AUTOSAR XML (schema 4-3-0)
package /ComponentTypes
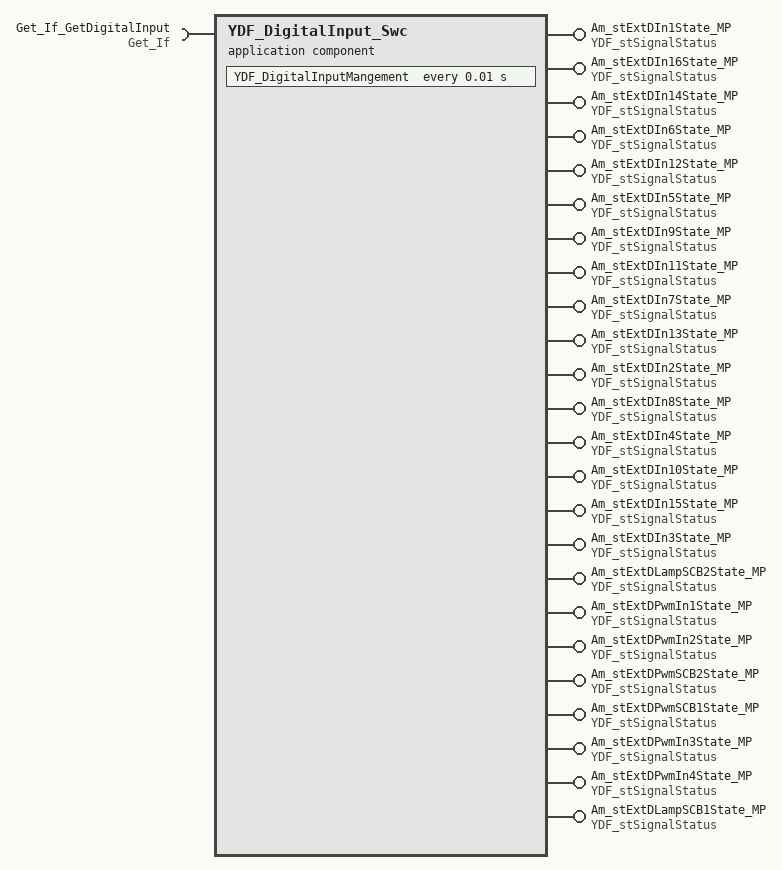
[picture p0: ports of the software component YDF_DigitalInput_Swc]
  application sw component type YDF_DigitalInput_Swc
    provide port Am_stExtDIn1State_MP: nonqueued-sender-com-spec{data-element=SignalStatus, init-value=0}, provided-interface=YDF_stSignalStatus
    provide port Am_stExtDIn16State_MP: nonqueued-sender-com-spec{data-element=SignalStatus, init-value=0}, provided-interface=YDF_stSignalStatus
    require port Get_If_GetDigitalInput: required-interface=Get_If
      required-com-specs:
        Get_Ad_Result
        Get_io_inResult
        Get_BTS_OutResult
        Get_CAN_ActiveInf
        Icu_17_GtmCcu6_PWMIN_CH{1..4}
        Icu_17_GtmCcu6_PWMIN_PWMSCB1
        Icu_17_GtmCcu6_PWMIN_PWMSCB2
        Icu_17_GtmCcu6_PWMIN_LAMPSCB1
        Icu_17_GtmCcu6_PWMIN_LAMPSCB2
        Get_Bottom_Ver
        Get_SentData
        Get_Level_OutResult
        Get_PwmOrLevel_OutResult
        Get_Motor_OutResult
    22 x provide port, all with nonqueued-sender-com-spec{data-element=SignalStatus, init-value=0}, provided-interface=YDF_stSignalStatus:
      Am_stExtDIn14State_MP
      Am_stExtDIn6State_MP
      Am_stExtDIn12State_MP
      Am_stExtDIn5State_MP
      Am_stExtDIn9State_MP
      Am_stExtDIn11State_MP
      Am_stExtDIn7State_MP
      Am_stExtDIn13State_MP
      Am_stExtDIn2State_MP
      Am_stExtDIn8State_MP
      Am_stExtDIn4State_MP
      Am_stExtDIn10State_MP
      Am_stExtDIn15State_MP
      Am_stExtDIn3State_MP
      Am_stExtDLampSCB2State_MP
      Am_stExtDPwmIn1State_MP
      Am_stExtDPwmIn2State_MP
      Am_stExtDPwmSCB2State_MP
      Am_stExtDPwmSCB1State_MP
      Am_stExtDPwmIn3State_MP
      Am_stExtDPwmIn4State_MP
      Am_stExtDLampSCB1State_MP
    behavior YDF_DigitalInput_Swc_InternalBehavior
      timing event TMT_YDF_DigitalInputMangement: start-on-event=YDF_DigitalInputMangement, period=0.01
      runnable YDF_DigitalInputMangement
        data-send-points:
          24 x access:
            SEND_Am_stExtDIn16State_MP_SignalStatus: accessed-variable=Am_stExtDIn16State_MP.SignalStatus
            SEND_Am_stExtDIn1State_MP_SignalStatus: accessed-variable=Am_stExtDIn1State_MP.SignalStatus
            SEND_Am_stExtDIn{10..15}State_MP_SignalStatus: accessed-variable=Am_stExtDIn{10..15}State_MP.SignalStatus
            SEND_Am_stExtDIn{2..9}State_MP_SignalStatus: accessed-variable=Am_stExtDIn{2..9}State_MP.SignalStatus
            SEND_Am_stExtDLampSCB1State_MP_SignalStatus: accessed-variable=Am_stExtDLampSCB1State_MP.SignalStatus
            SEND_Am_stExtDLampSCB2State_MP_SignalStatus: accessed-variable=Am_stExtDLampSCB2State_MP.SignalStatus
            SEND_Am_stExtDPwmIn{1..4}State_MP_SignalStatus: accessed-variable=Am_stExtDPwmIn{1..4}State_MP.SignalStatus
            SEND_Am_stExtDPwmSCB1State_MP_SignalStatus: accessed-variable=Am_stExtDPwmSCB1State_MP.SignalStatus
            SEND_Am_stExtDPwmSCB2State_MP_SignalStatus: accessed-variable=Am_stExtDPwmSCB2State_MP.SignalStatus
        sync call SC_Get_If_GetDigitalInput_Get_io_inResult: operation=Get_If_GetDigitalInput.Get_io_inResult
  swc implementation YDF_DigitalInput_Swc_Implementation: behavior=YDF_DigitalInput_Swc_InternalBehavior
